# SAM9X75D1G device description
Architecture: ARM926EJ-S; Family: SAM9; Series: SAM9X7
Registers are 32-bit, read-write, reset 0x0 unless marked. A register's access mark holds for its fields unless they carry their own. Offsets are from the block's base; [hi:lo] are bit positions; {n}, {i} and the like mark numbered series.

## ADC — Analog-to-Digital Converter
Instances: ADC 0xF804C000
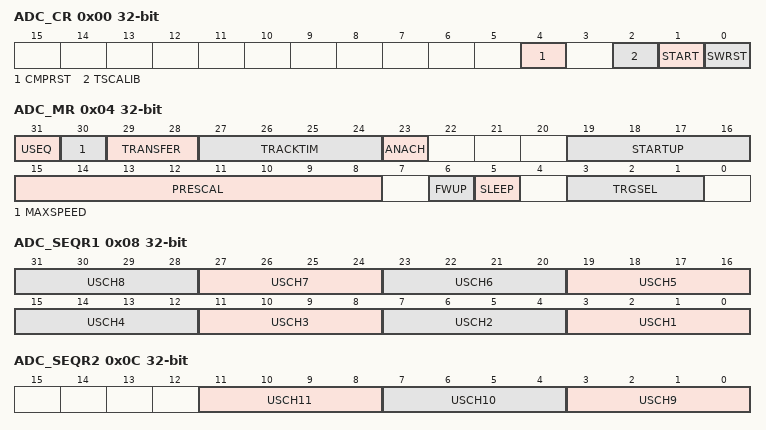
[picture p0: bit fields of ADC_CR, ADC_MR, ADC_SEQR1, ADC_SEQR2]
0x00 ADC_CR wo reset not defined — Control Register
  [4] CMPRST — Comparison Restart
    0=No effect; 1=Stops the conversion result storage until the next comparison match
  [2] TSCALIB — Touchscreen Calibration
    0=No effect; 1=Programs screen calibration (VDD/GND measurement)
  [1] START — Start Conversion
    0=No effect; 1=Triggers a single sequence of analog-to-digital conversions if ADC_TRGR.TRGMOD=0
  [0] SWRST — Software Reset
    0=No effect; 1=Resets the ADC
0x04 ADC_MR — Mode Register
  [31] USEQ — User Sequence Enable
    0=NUM_ORDER (Normal mode: The controller converts channels in a simple numeric order depending only on the channel index.); 1=REG_ORDER (User Sequence mode: The sequence respects what is defined in ADC_SEQR1 and ADC_SEQR2 registers and can be used to convert the same channel several times.)
  [30] MAXSPEED — Maximum Sampling Rate Enable in Freerun Mode
  [29:28] TRANSFER — Transfer Time
  [27:24] TRACKTIM — Tracking Time
  [23] ANACH — Analog Change
    0=NONE (No analog change on channel switching: DIFF0 is used for all channels.); 1=ALLOWED (Allows different analog settings for each channel. See ADC Channel Offset RegisterChannel Configuration Register.)
  [19:16] STARTUP — Startup Time
    0=SUT0 (0 periods of ADCCLK); 1=SUT8 (8 periods of ADCCLK); 2=SUT16 (16 periods of ADCCLK); 3=SUT24 (24 periods of ADCCLK); 4=SUT64 (64 periods of ADCCLK); 5=SUT80 (80 periods of ADCCLK); 6=SUT96 (96 periods of ADCCLK); 7=SUT112 (112 periods of ADCCLK); 8=SUT512 (512 periods of ADCCLK); 9=SUT576 (576 periods of ADCCLK); 10=SUT640 (640 periods of ADCCLK); 11=SUT704 (704 periods of ADCCLK); 12=SUT768 (768 periods of ADCCLK); 13=SUT832 (832 periods of ADCCLK); 14=SUT896 (896 periods of ADCCLK); 15=SUT960 (960 periods of ADCCLK)
  [15:8] PRESCAL — Prescaler Rate Selection
  [6] FWUP — Fast Wakeup
    0=OFF (If SLEEP is 1, then both ADC core and reference voltage circuitry are OFF between conversions); 1=ON (If SLEEP is 1, then Fast Wakeup Sleep mode: The voltage reference is ON between conversions and ADC core is OFF)
  [5] SLEEP — Sleep Mode
    0=NORMAL (Normal Mode: The ADC core and reference voltage circuitry are kept ON between conversions.); 1=SLEEP (Sleep Mode: The wakeup time can be modified by programming the FWUP bit.)
  [3:1] TRGSEL — Trigger Selection
    0=ADC_TRIG0 (ADTRG); 1=ADC_TRIG1 (TIOA0); 2=ADC_TRIG2 (TIOA1); 3=ADC_TRIG3 (TIOA2); 4=ADC_TRIG4 (PWM event line 0); 5=ADC_TRIG5 (PWM event line 1); 6=ADC_TRIG6 (TIOA3); 7=ADC_TRIG7 (RTCOUT1)
0x08 ADC_SEQR1 — Channel Sequence Register 1
  [4n-1:4n-4] USCH{n} (n=1..8) — User Sequence Number {n}
0x0C ADC_SEQR2 — Channel Sequence Register 2
  [11:8] USCH11 — User Sequence Number 11
  [7:4] USCH10 — User Sequence Number 10
  [3:0] USCH9 — User Sequence Number 9
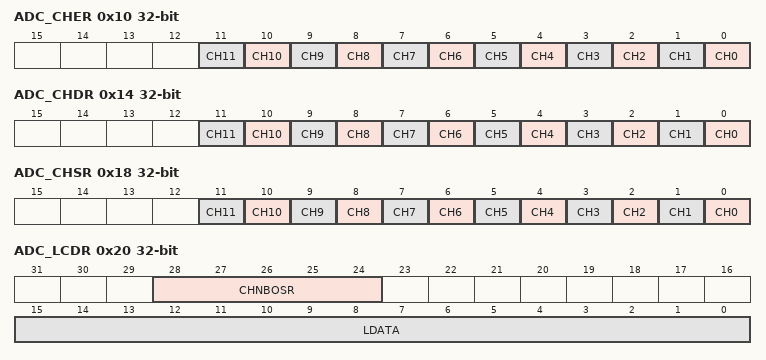
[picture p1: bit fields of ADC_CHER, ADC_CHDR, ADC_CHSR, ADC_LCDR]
0x10 ADC_CHER wo reset not defined (atomic set of ADC_CHSR) — Channel Enable Register
  [all] fields
    0=No effect; 1=Enables the corresponding channel
  [n] CH{n} (n=0..11) — Channel {n} Enable
0x14 ADC_CHDR wo reset not defined (atomic clear of ADC_CHSR) — Channel Disable Register
  [all] fields
    0=No effect; 1=Disables the corresponding channel
  [n] CH{n} (n=0..11) — Channel {n} Disable
0x18 ADC_CHSR ro — Channel Status Register
  [all] fields
    0=The corresponding channel (or part of sequence, see ADC_SEQyR.USCHx field) is disabled; 1=The corresponding channel (or part of sequence, see ADC_SEQyR.USCHx field) is enabled
  [n] CH{n} (n=0..11) — Channel {n} Status
0x20 ADC_LCDR ro — Last Converted Data Register
  [28:24] CHNBOSR — Channel Number in Oversampling Mode
  [15:0] LDATA — Last Data Converted
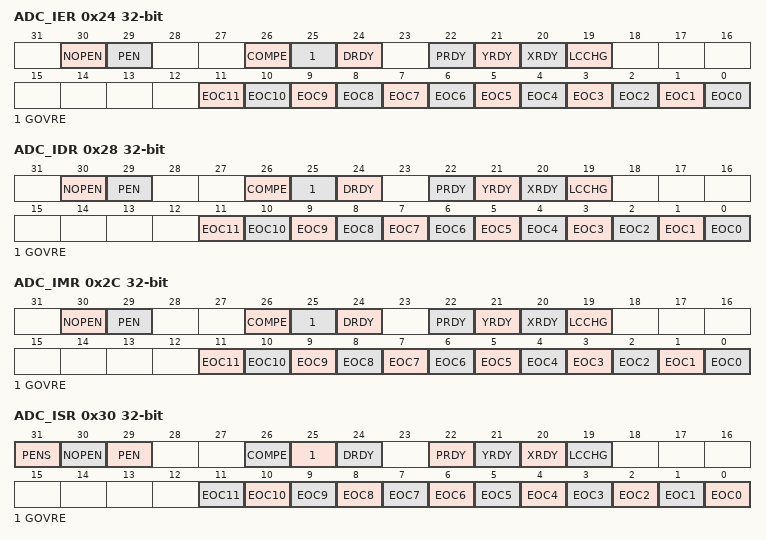
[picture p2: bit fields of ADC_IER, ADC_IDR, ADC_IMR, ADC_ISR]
0x24 ADC_IER wo reset not defined (atomic set of ADC_IMR) — Interrupt Enable Register
  [30] NOPEN — No Pen Contact Interrupt Enable
  [29] PEN — Pen Contact Interrupt Enable
  [26] COMPE — Comparison Event Interrupt Enable
  [25] GOVRE — General Overrun Error Interrupt Enable
  [24] DRDY — Data Ready Interrupt Enable
  [22] PRDY — Touchscreen Measure Pressure Ready Interrupt Enable
  [21] YRDY — Touchscreen Measure YPOS Ready Interrupt Enable
  [20] XRDY — Touchscreen Measure XPOS Ready Interrupt Enable
  [19] LCCHG — Last Channel Change Interrupt Enable
  [n] EOC{n} (n=0..11) — End of Conversion Interrupt Enable {n}
0x28 ADC_IDR wo reset not defined (atomic clear of ADC_IMR) — Interrupt Disable Register
  [30] NOPEN — No Pen Contact Interrupt Disable
  [29] PEN — Pen Contact Interrupt Disable
  [26] COMPE — Comparison Event Interrupt Disable
  [25] GOVRE — General Overrun Error Interrupt Disable
  [24] DRDY — Data Ready Interrupt Disable
  [22] PRDY — Touchscreen Measure Pressure Ready Interrupt Disable
  [21] YRDY — Touchscreen Measure YPOS Ready Interrupt Disable
  [20] XRDY — Touchscreen Measure XPOS Ready Interrupt Disable
  [19] LCCHG — Last Channel Change Interrupt Disable
  [n] EOC{n} (n=0..11) — End of Conversion Interrupt Disable {n}
0x2C ADC_IMR ro — Interrupt Mask Register
  [30] NOPEN — No Pen Contact Interrupt Mask
  [29] PEN — Pen Contact Interrupt Mask
  [26] COMPE — Comparison Event Interrupt Mask
  [25] GOVRE — General Overrun Error Interrupt Mask
  [24] DRDY — Data Ready Interrupt Mask
  [22] PRDY — Touchscreen Measure Pressure Ready Interrupt Mask
  [21] YRDY — Touchscreen Measure YPOS Ready Interrupt Mask
  [20] XRDY — Touchscreen Measure XPOS Ready Interrupt Mask
  [19] LCCHG — Last Channel Change Interrupt Disable
  [n] EOC{n} (n=0..11) — End of Conversion Interrupt Mask {n}
0x30 ADC_ISR ro — Interrupt Status Register
  [31] PENS — Pen Detect Status
    0=The pen does not press the screen; 1=The pen presses the screen
  [30] NOPEN — No Pen Contact (cleared on read)
    0=No loss of pen contact since the last read of ADC_ISR; 1=At least one loss of pen contact since the last read of ADC_ISR
  [29] PEN — Pen contact (cleared on read)
    0=No pen contact since the last read of ADC_ISR; 1=At least one pen contact since the last read of ADC_ISR
  [26] COMPE — Comparison Event (cleared on read)
    0=No comparison event since the last read of ADC_ISR; 1=At least one comparison event (defined in ADC_EMR and ADC_CWR) has occurred since the last read of ADC_ISR
  [25] GOVRE — General Overrun Error (cleared on read)
    0=No general overrun error occurred since the last read of ADC_ISR; 1=At least one general overrun error has occurred since the last read of ADC_ISR
  [24] DRDY — Data Ready (automatically set / cleared)
    0=No data has been converted since the last read of ADC_LCDR; 1=At least one data has been converted and is available in ADC_LCDR
  [22] PRDY — Touchscreen Pressure Measure Ready (cleared on read)
    0=No measure has been performed since the last read of ADC_PRESSR; 1=At least one measure has been performed since the last read of ADC_ISR
  [21] YRDY — Touchscreen YPOS Measure Ready (cleared on read)
    0=No measure has been performed since the last read of ADC_YPOSR; 1=At least one measure has been performed since the last read of ADC_ISR
  [20] XRDY — Touchscreen XPOS Measure Ready (cleared on read)
    0=No measure has been performed since the last read of ADC_XPOSR; 1=At least one measure has been performed since the last read of ADC_ISR
  [19] LCCHG — Last Channel Change (cleared on read)
    0=There is no comparison match (defined in the Last Channel Compare Window register (ADC_LCCWR) since the last read of ADC_ISR; 1=The converted value reported on ADC_CDRNB_CHANNEL-1 has changed since the last read of ADC_ISR, according to what is defined in ADC_LCTMR and ADC_LCCWR
  [n] EOC{n} (n=0..11) — End of Conversion {n} (automatically set / cleared)
    0=The corresponding analog channel is disabled, or the conversion is not finished. This flag is cleared when reading the corresponding ADC_CDRx registers.; 1=The corresponding analog channel is enabled and conversion is complete
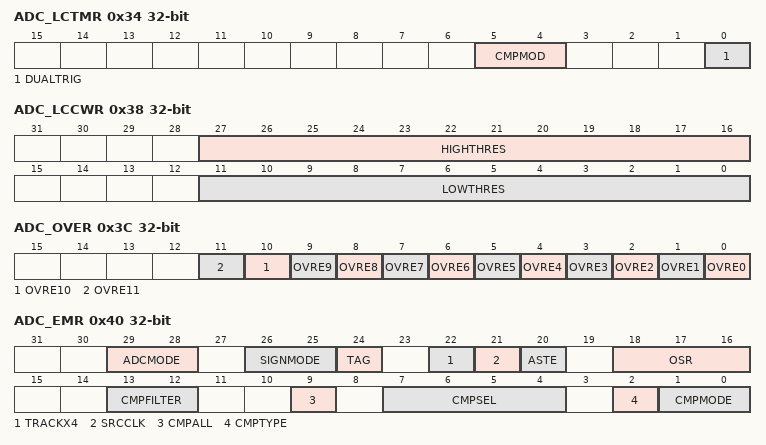
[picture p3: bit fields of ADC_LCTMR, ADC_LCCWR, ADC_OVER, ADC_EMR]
0x34 ADC_LCTMR — Last Channel Trigger Mode Register
  [5:4] CMPMOD — Last Channel Comparison Mode
    0=LOW (Generates the ADC_ISR.LCCHG flag when the converted data is lower than the low threshold of the window.); 1=HIGH (Generates the ADC_ISR.LCCHG flag when the converted data is higher than the high threshold of the window.); 2=IN (Generates the ADC_ISR.LCCHG flag when the converted data is in the comparison window.); 3=OUT (Generates the ADC_ISR.LCCHG flag when the converted data is out of the comparison window.)
  [0] DUALTRIG — Dual Trigger ON
    0=All channels are triggered by event defined by ADC_MR.TRGSEL; 1=Last channel (higher index) trigger period is defined by RTC_MR.OUT1
0x38 ADC_LCCWR — Last Channel Compare Window Register
  [27:16] HIGHTHRES — High Threshold
  [11:0] LOWTHRES — Low Threshold
0x3C ADC_OVER ro — Overrun Status Register
  [all] fields
    0=No overrun error on the corresponding channel since the last read of ADC_OVER; 1=An overrun error has occurred on the corresponding channel since the last read of ADC_OVER
  [n] OVRE{n} (n=0..11) — Overrun Error {n}
0x40 ADC_EMR — Extended Mode Register
  [29:28] ADCMODE — ADC Running Mode
    0=NORMAL (Normal mode of operation.); 1=OFFSET_ERROR (Offset Error mode to measure the offset error. See Table 7-6.); 2=GAIN_ERROR_HIGH (Gain Error mode to measure the gain error. See Table 7-6.); 3=GAIN_ERROR_LOW (Gain Error mode to measure the gain error. See Table 7-6.)
  [26:25] SIGNMODE
    0=SE_UNSG_DF_SIGN (Single-Ended channels: Unsigned conversions. Pseudo-differential channels and Differential channels: Signed conversions.); 1=SE_SIGN_DF_UNSG (Single-Ended channels: Signed conversions. Pseudo-differential channels and Differential channels: Unsigned conversions.); 2=ALL_UNSIGNED (All channels: Unsigned conversions.); 3=ALL_SIGNED (All channels: Signed conversions.)
  [24] TAG — Tag of ADC_LCDR
    0=Sets ADC_LCDR.CHNB field to zero; 1=Appends the channel number to the conversion result in ADC_LCDR
  [22] TRACKX4 — Tracking Time x4
    0=The ADC_MR.TRACKTIM field effect is multiplied by 1; 1=The ADC_MR.TRACKTIM field effect is multiplied by 4
  [21] SRCCLK — External Clock Selection
    0=PERIPH_CLK (The peripheral clock is the source for the ADC prescaler.); 1=GCLK (GCLK is the source clock for the ADC prescaler, thus the ADC clock can be independent of the core/peripheral clock.)
  [20] ASTE — Averaging on Single Trigger Event
    0=MULTI_TRIG_AVERAGE (The average requests several trigger events.); 1=SINGLE_TRIG_AVERAGE (The average requests only one trigger event.)
  [18:16] OSR — Over Sampling Rate
    0=NO_AVERAGE (No averaging. ADC sample rate is maximum.); 1=1-bit enhanced resolution by averaging. ADC sample rate divided by 4.; 2=2-bit enhanced resolution by averaging. ADC sample rate divided by 16.; 3=3-bit enhanced resolution by averaging. ADC sample rate divided by 64.; 4=4-bit enhanced resolution by averaging. ADC sample rate divided by 256.
  [13:12] CMPFILTER — Compare Event Filtering
  [9] CMPALL — Compare All Channels
    0=Only channel indicated in CMPSEL field is compared; 1=All channels are compared
  [7:4] CMPSEL — Comparison Selected Channel
  [2] CMPTYPE — Comparison Type
    0=FLAG_ONLY (Any conversion is performed and comparison function drives the ADC_ISR.COMPE flag.); 1=START_CONDITION (Comparison conditions must be met to start the storage of all conversions until the ADC_CR.CMPRST bit is set.)
  [1:0] CMPMODE — Comparison Mode
    0=LOW (When the converted data is lower than the low threshold of the window, generates the ADC_ISR.COMPE flag.); 1=HIGH (When the converted data is higher than the high threshold of the window, generates the ADC_ISR.COMPE flag.); 2=IN (When the converted data is in the comparison window, generates the ADC_ISR.COMPE flag.); 3=OUT (When the converted data is out of the comparison window, generates the ADC_ISR.COMPE flag.)
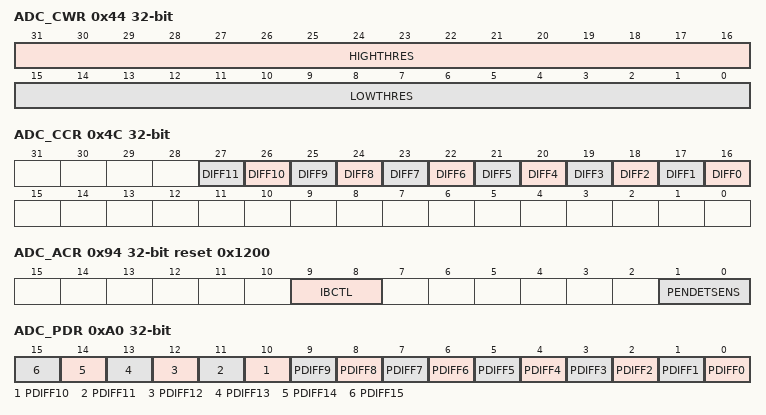
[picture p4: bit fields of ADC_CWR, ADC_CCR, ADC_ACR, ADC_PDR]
0x44 ADC_CWR — Compare Window Register
  [31:16] HIGHTHRES — High Threshold
  [15:0] LOWTHRES — Low Threshold
0x4C ADC_CCR — Channel Configuration Register
  [all] fields
    0=Corresponding channel is set in Single-ended mode; 1=Corresponding channel is set in Differential mode
  [n+16] DIFF{n} (n=0..11) — Differential Inputs for Channel {n}
{0x50+4i} ADC_CDR[{i}] (i=0..11) ro — Channel Data Register x
  [15:0] DATA — Converted Data
0x94 ADC_ACR reset 0x1200 — Analog Control Register
  [9:8] IBCTL — ADC Bias Current Control
  [1:0] PENDETSENS — Pen Detection Sensitivity
0xA0 ADC_PDR — Pseudo-Differential Register
  [all] fields
    0=The channel is configured as defined by ADC_CCR.DIFFx bit; 1=The channel is configured in pseudo-differential mode
  [n] PDIFF{n} (n=0..15) — Pseudo-Differential Inputs for Channel {n}
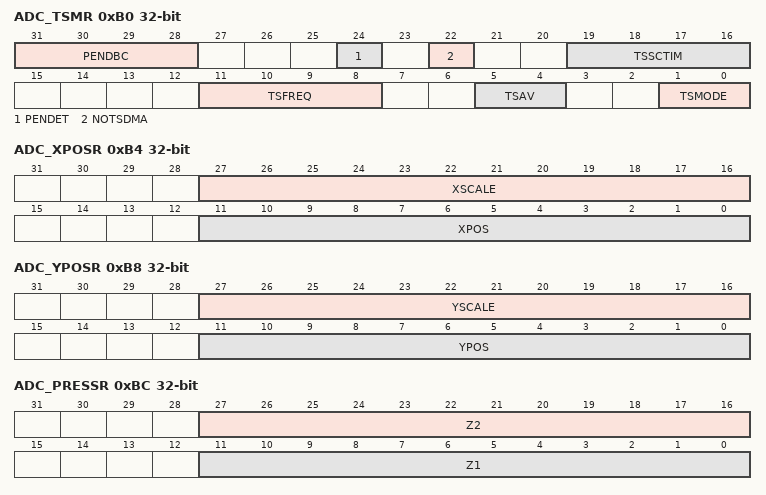
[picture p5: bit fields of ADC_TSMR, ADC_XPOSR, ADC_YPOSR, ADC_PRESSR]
0xB0 ADC_TSMR — Touchscreen Mode Register
  [31:28] PENDBC — Pen Detect Debouncing Period
  [24] PENDET — Pen Contact Detection Enable
    0=Pen contact detection disabled; 1=Pen contact detection enabled
  [22] NOTSDMA — No TouchScreen DMA
    0=XPOS, YPOS, Z1, Z2 are transmitted in ADC_LCDR; 1=XPOS, YPOS, Z1, Z2 are never transmitted in ADC_LCDR, therefore the buffer does not contains touchscreen values
  [19:16] TSSCTIM — Touchscreen Switches Closure Time
  [11:8] TSFREQ — Touchscreen Frequency
  [5:4] TSAV — Touchscreen Average
    0=NO_FILTER (No Filtering. Only one ADC conversion per measure); 1=AVG2CONV (Averages 2 ADC conversions); 2=AVG4CONV (Averages 4 ADC conversions); 3=AVG8CONV (Averages 8 ADC conversions)
  [1:0] TSMODE — Touchscreen Mode
    0=NONE (No Touchscreen); 1=4_WIRE_NO_PM (4-wire Touchscreen without pressure measurement); 2=4_WIRE (4-wire Touchscreen with pressure measurement); 3=5_WIRE (5-wire Touchscreen)
0xB4 ADC_XPOSR ro — Touchscreen X Position Register
  [27:16] XSCALE — Scale of XPOS
  [11:0] XPOS — X Position
0xB8 ADC_YPOSR ro — Touchscreen Y Position Register
  [27:16] YSCALE — Scale of YPOS
  [11:0] YPOS — Y Position
0xBC ADC_PRESSR ro — Touchscreen Pressure Register
  [27:16] Z2 — Data of Z2 Measurement
  [11:0] Z1 — Data of Z1 Measurement
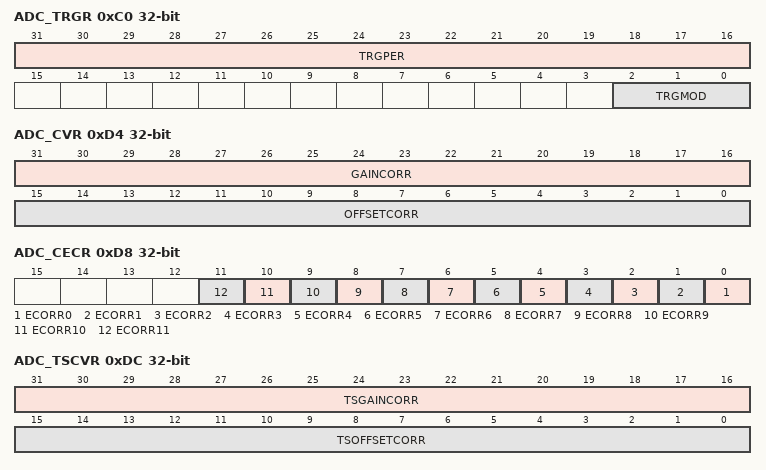
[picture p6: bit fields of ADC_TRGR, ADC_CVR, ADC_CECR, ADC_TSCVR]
0xC0 ADC_TRGR — Trigger Register
  [31:16] TRGPER — Trigger Period
  [2:0] TRGMOD — Trigger Mode
    0=NO_TRIGGER (No hardware trigger enabled, only software trigger can start conversions); 1=EXT_TRIG_RISE (Rising edge of the selected hardware trigger event, defined in ADC_MR.TRGSEL); 2=EXT_TRIG_FALL (Falling edge of the selected hardware trigger event); 3=EXT_TRIG_ANY (Any edge of the selected hardware trigger event); 4=PEN_TRIG (Pen Detect Trigger (shall be selected only if PENDET is set and TSMODE > 0)); 5=PERIOD_TRIG (ADC internal hardware periodic trigger (see field TRGPER)); 6=CONTINUOUS (Continuous mode)
0xD4 ADC_CVR — Correction Values Register
  [31:16] GAINCORR — Gain Correction
  [15:0] OFFSETCORR — Offset Correction
0xD8 ADC_CECR — Channel Error Correction Register
  [all] fields
    0=Automatic error correction is disabled for channel x; 1=Automatic error correction is enabled for channel x
  [n] ECORR{n} (n=0..11) — Error Correction Enable for channel {n}
0xDC ADC_TSCVR — Touchscreen Correction Values Register
  [31:16] TSGAINCORR — Touchscreen Gain Correction
  [15:0] TSOFFSETCORR — Touchscreen Offset Correction
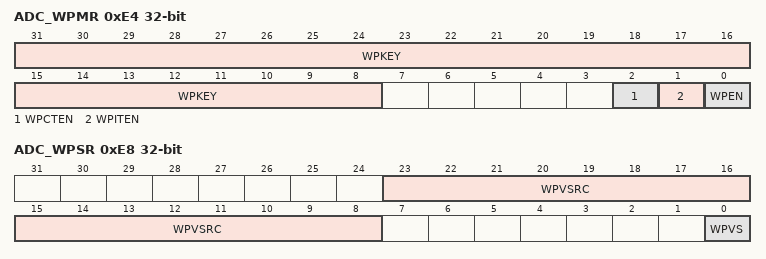
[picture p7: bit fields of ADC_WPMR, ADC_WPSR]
0xE4 ADC_WPMR — Write Protection Mode Register
  [31:8] WPKEY — Write Protection Key
    0x414443=PASSWD (Writing any other value in this field aborts the write operation of the WPEN bit. Always reads as 0)
  [2] WPCTEN — Write Protection Control Enable
    0=Disables the write protection on control registers if WPKEY corresponds to 0x414443 ("ADC" in ASCII); 1=Enables the write protection on control registers if WPKEY corresponds to 0x414443 ("ADC" in ASCII)
  [1] WPITEN — Write Protection Interrupt Enable
    0=Disables the write protection on interrupt registers if WPKEY corresponds to 0x414443 ("ADC" in ASCII); 1=Enables the write protection on interrupt registers if WPKEY corresponds to 0x414443 ("ADC" in ASCII)
  [0] WPEN — Write Protection Enable
    0=Disables the write protection if WPKEY value corresponds to 0x414443 ("ADC" in ASCII); 1=Enables the write protection if WPKEY value corresponds to 0x414443 ("ADC" in ASCII)
0xE8 ADC_WPSR ro — Write Protection Status Register
  [23:8] WPVSRC — Write Protection Violation Source
  [0] WPVS — Write Protection Violation Status
    0=No write protection violation has occurred since the last read of ADC_WPSR; 1=A write protection violation has occurred since the last read of ADC_WPSR. If this violation is an unauthorized attempt to write a protected register, the associated violation is reported into field WPVSRC.
